# NPCX490M register map
File version: 1.0
ARM 32-bit Cortex-M4 Microcontroller based device, CPU clock up to 100MHz, etc.
Registers are 8-bit, read-write, reset 0x0 unless marked. A register's access mark holds for its fields unless they carry their own. Offsets are from the block's base; lines under a group give offsets from that group; [hi:lo] are bit positions; {n}, {i} and the like mark numbered series; 'fields as' and 'values as' point back to an identical list; <NAME> marks a mode.

## Memory map
0x40007000 OTPI size 0xD0
0x40008000 SMB4 size 0xF8
0x40009000 SMB0 size 0xF8
0x4000A000 ESPI size 0x4B60
0x4000B000 SMB1 size 0xF8
0x4000C000 MDC size 0xC08
0x4000D000 PMC size 0x138
0x4000E000 CORE2HOST size 0x58
0x4000F000 SHI size 0x900
0x40010000 SHM size 0x270
0x40010080 ESHM size 0x270
0x40011000 GDMA1 size 0x200
0x40011100 MDMA1 size 0x1A0
0x40011200 MDMA2 size 0x1A0
0x40011300 MDMA3 size 0x1A0
0x40011400 MDMA4 size 0x1A0
0x40011500 MDMA5 size 0x1A0
0x40011600 MDMA6 size 0x1A0
0x40011700 MDMA7 size 0x1A0
0x40011A00 GDMA2 size 0x200
0x40017000 SMB5 size 0xF8
0x40018000 SMB6 size 0xF8
0x40019000 SMB7 size 0xF8
0x40020000 FIU_0 size 0x1F8
0x40021000 FIU_1 size 0x1F8
{0x40080000+0x2000*n} PWM{n} size 0x90 (n=0..7)
{0x40081000+0x2000*n} GPIO{n} size 0x40 (n=0..9)
0x40095000 GPIOA size 0x40
0x40097000 GPIOB size 0x40
0x40099000 GPIOC size 0x40
0x4009B000 GPIOD size 0x40
0x4009D000 GPIOE size 0x40
0x4009F000 GPIOF size 0x40
0x400A3000 KBS size 0x80
0x400A5000 SYS_GLUE size 0x228
0x400AF100 BBRM size 0x10
0x400B0000 ITIM32_1 size 0x60
0x400B1000 PS2 size 0x58
0x400B2000 ITIM32_2 size 0x60
0x400B4000 ITIM32_3 size 0x60
0x400B5000 HFCG size 0xF0
0x400B5100 LFCG size 0xA8
0x400B6000 ITIM32_4 size 0x60
0x400B7000 MTC size 0x40
0x400B8000 ITIM32_5 size 0x60
0x400BA000 ITIM32_6 size 0x60
0x400BB000 MIWU0 size 0x78
0x400BD000 MIWU1 size 0x78
0x400BE000 ITIM64 size 0x80
0x400BF000 MIWU2 size 0x78
0x400C0000 SMB2 size 0xF8
0x400C1000 MSWC size 0x148
0x400C2000 SMB3 size 0xF8
0x400C3000 DEV size 0x3D8
0x400C3000 SYS_CONFIG size 0x18A0
0x400C7000 KBC size 0x60
0x400C9000 PM1 size 0x88
0x400CB000 PM2 size 0x88
0x400CD000 PM3 size 0x88
0x400CF000 PM4 size 0x88
0x400D1000 ADC_IREF size 0x490
0x400D2000 SPIP size 0x28
0x400D4000 PECI size 0x280
0x400D5000 ADC_EREF size 0x490
0x400D7000 LCT size 0x70
0x400D8000 TWD size 0x88
0x400E0000 CR_UART1 size 0x168
0x400E1000 MFT16_1 size 0xE8
0x400E2000 CR_UART2 size 0x168
0x400E3000 MFT16_2 size 0xE8
0x400E4000 CR_UART3 size 0x168
0x400E5000 MFT16_3 size 0xE8
0x400E6000 CR_UART4 size 0x168
0x400F0000 I3C1 size 0x700
0x400F2000 I3C2 size 0x700
0x400F4000 I3C3 size 0x700
0x400F8000 FLM size 0x1800

## BBRM
Base 0x400AF100
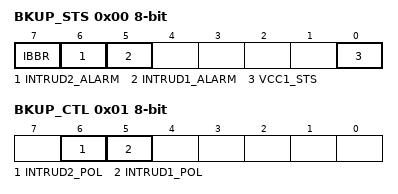
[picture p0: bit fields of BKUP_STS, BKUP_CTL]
0x00 BKUP_STS — BBRM Status Register (BKUP_STS)
  [7] IBBR — Invalid Battery-Backed RAM
  [6] INTRUD2_ALARM — Intruder2 Alarm
  [5] INTRUD1_ALARM — Intruder1 Alarm
  [0] VCC1_STS — VCC1 Power-Fail Status
0x01 BKUP_CTL — BBRM Control Register (BKUP_CTL)
  [6] INTRUD2_POL — Intruder2 Polarity
  [5] INTRUD1_POL — Intruder1 Polarity

## CORE2HOST
Base 0x4000E000
0x00 IHIOA 16-bit — Indirect Host I/O Address Register (IHIOA)
  [7:0] IH_OFS — Indirect Host I/O Offset
0x02 IHD — Indirect Host Data Register (IHD)
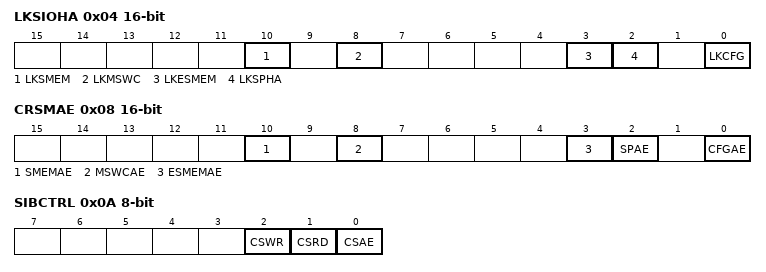
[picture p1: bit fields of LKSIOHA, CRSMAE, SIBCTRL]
0x04 LKSIOHA 16-bit (reset mask 0xFF) — Lock Host Access Register (LKSIOHA)
  [10] LKSMEM — Lock Shared Memory Host Access
  [8] LKMSWC — Lock Mobile System Wake-Up Control Host Access
  [3] LKESMEM — Lock Extended Shared Memory Host Access
  [2] LKSPHA — Lock Serial Port Host Access
  [0] LKCFG — Lock Configuration Registers Host Access
0x08 CRSMAE 16-bit (reset mask 0xFF) — Core-to-Host Modules Access Enable Register (CRSMAE)
  [10] SMEMAE — Shared Memory Core Access Enable
  [8] MSWCAE — Mobile System Wake-Up Control Access Enable
  [3] ESMEMAE — ESHM Core Access Enable
  [2] SPAE — Serial Port Core Access Enable
  [0] CFGAE — Configuration Registers Core Access Enable
0x0A SIBCTRL — HMIB Control Register (SIBCTRL)
  [2] CSWR — Core Write to Host Modules
  [1] CSRD — Core Read from Host Modules
  [0] CSAE — Core-to-Host Modules Access Enable
